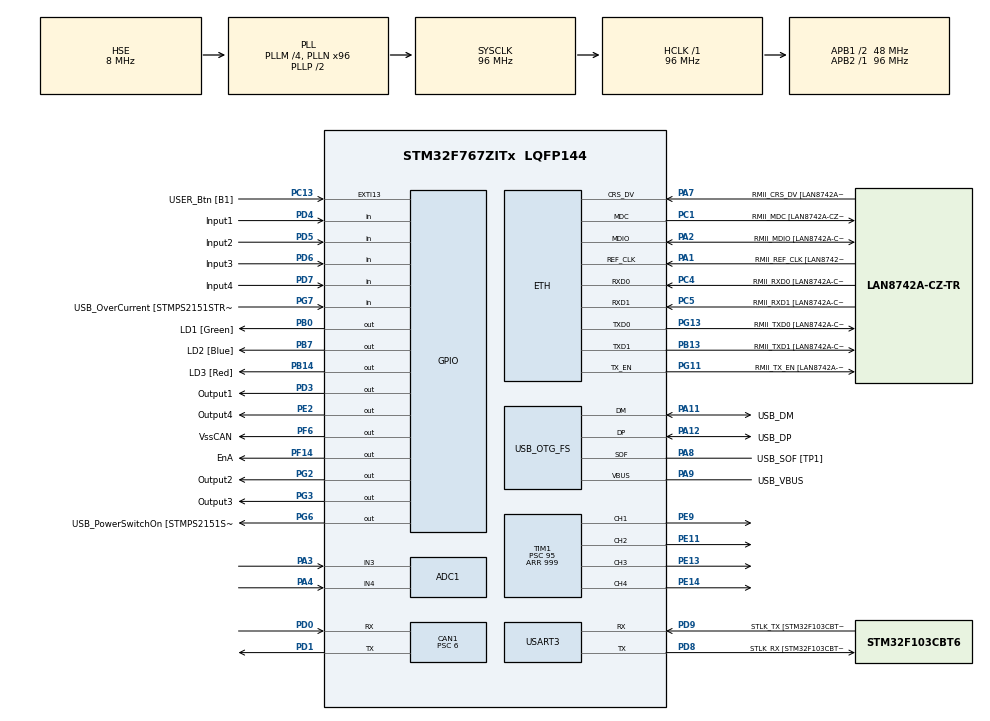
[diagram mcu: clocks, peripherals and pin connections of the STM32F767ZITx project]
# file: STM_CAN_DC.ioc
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ADC1.Channel-0\#ChannelRegularConversion=ADC_CHANNEL_3
ADC1.Channel-1\#ChannelRegularConversion=ADC_CHANNEL_4
ADC1.DMAContinuousRequests=ENABLE
ADC1.ExternalTrigConv=ADC_EXTERNALTRIGCONV_T1_TRGO
ADC1.NbrOfConversion=2
ADC1.NbrOfConversionFlag=1
ADC1.Rank-0\#ChannelRegularConversion=1
ADC1.Rank-1\#ChannelRegularConversion=2
ADC1.SamplingTime-0\#ChannelRegularConversion=ADC_SAMPLETIME_3CYCLES
ADC1.SamplingTime-1\#ChannelRegularConversion=ADC_SAMPLETIME_3CYCLES
ADC1.ScanConvMode=ADC_SCAN_ENABLE
ADC1.master=1
CAN1.BS1=CAN_BS1_4TQ
CAN1.BS2=CAN_BS2_3TQ
CAN1.CalculateTimeQuantum=125.0
CAN1.Prescaler=6
Dma.ADC1.0.Direction=DMA_PERIPH_TO_MEMORY
Dma.ADC1.0.FIFOMode=DMA_FIFOMODE_DISABLE
Dma.ADC1.0.Instance=DMA2_Stream0
Dma.ADC1.0.MemDataAlignment=DMA_MDATAALIGN_HALFWORD
Dma.ADC1.0.MemInc=DMA_MINC_ENABLE
Dma.ADC1.0.Mode=DMA_CIRCULAR
Dma.ADC1.0.PeriphDataAlignment=DMA_PDATAALIGN_HALFWORD
Dma.ADC1.0.PeriphInc=DMA_PINC_DISABLE
Dma.ADC1.0.Priority=DMA_PRIORITY_LOW
Dma.Request0=ADC1
ETH.MediaInterface=ETH_MEDIA_INTERFACE_RMII
ETH.PHY_Name=LAN8742A_PHY_ADDRESS
ETH.PHY_Value=0
ETH.PhyAddress=0
Mcu.Family=STM32F7
Mcu.Name=STM32F767ZITx
Mcu.Package=LQFP144
NVIC.CAN1_RX0_IRQn=true\:0\:0\:false\:false\:true\:true\:true
NVIC.CAN1_RX1_IRQn=true\:0\:0\:false\:false\:true\:true\:true
NVIC.CAN1_TX_IRQn=true\:0\:0\:false\:false\:true\:true\:true
NVIC.DMA2_Stream0_IRQn=true\:0\:0\:false\:false\:true\:false\:true
NVIC.EXTI15_10_IRQn=true\:0\:0\:false\:false\:true\:true\:true
NVIC.PriorityGroup=NVIC_PRIORITYGROUP_4
PA1.GPIO_Label=RMII_REF_CLK [LAN8742A-CZ-TR_REFCLK0]
PA1.Mode=RMII
PA1.Signal=ETH_REF_CLK
PA10.GPIO_Label=USB_ID
PA10.Signal=USB_OTG_FS_ID
PA11.GPIO_Label=USB_DM
PA11.Mode=Device_Only
PA11.Signal=USB_OTG_FS_DM
PA12.GPIO_Label=USB_DP
PA12.Mode=Device_Only
PA12.Signal=USB_OTG_FS_DP
PA13.GPIO_Label=TMS
PA13.Mode=Serial_Wire
PA13.Signal=SYS_JTMS-SWDIO
PA14.GPIO_Label=TCK
PA14.Mode=Serial_Wire
PA14.Signal=SYS_JTCK-SWCLK
PA2.GPIO_Label=RMII_MDIO [LAN8742A-CZ-TR_MDIO]
PA2.Mode=RMII
PA2.Signal=ETH_MDIO
PA3.Signal=ADCx_IN3
PA4.Signal=ADCx_IN4
PA7.GPIO_Label=RMII_CRS_DV [LAN8742A-CZ-TR_CRS_DV]
PA7.Mode=RMII
PA7.Signal=ETH_CRS_DV
PA8.GPIO_Label=USB_SOF [TP1]
PA8.Mode=Activate_SOF_FS
PA8.Signal=USB_OTG_FS_SOF
PA9.GPIO_Label=USB_VBUS
PA9.Mode=Activate_VBUS
PA9.Signal=USB_OTG_FS_VBUS
PB0.GPIO_Label=LD1 [Green]
PB0.Signal=GPIO_Output
PB13.GPIO_Label=RMII_TXD1 [LAN8742A-CZ-TR_TXD1]
PB13.Mode=RMII
PB13.Signal=ETH_TXD1
PB14.GPIO_Label=LD3 [Red]
PB14.Signal=GPIO_Output
PB3.GPIO_Label=SWO
PB3.Signal=SYS_JTDO-SWO
PB7.GPIO_Label=LD2 [Blue]
PB7.Signal=GPIO_Output
PC1.GPIO_Label=RMII_MDC [LAN8742A-CZ-TR_MDC]
PC1.Mode=RMII
PC1.Signal=ETH_MDC
PC13.GPIO_Label=USER_Btn [B1]
PC13.Signal=GPXTI13
PC14/OSC32_IN.Mode=LSE-External-Oscillator
PC14/OSC32_IN.Signal=RCC_OSC32_IN
PC15/OSC32_OUT.Mode=LSE-External-Oscillator
PC15/OSC32_OUT.Signal=RCC_OSC32_OUT
PC4.GPIO_Label=RMII_RXD0 [LAN8742A-CZ-TR_RXD0]
PC4.Mode=RMII
PC4.Signal=ETH_RXD0
PC5.GPIO_Label=RMII_RXD1 [LAN8742A-CZ-TR_RXD1]
PC5.Mode=RMII
PC5.Signal=ETH_RXD1
PD0.GPIO_PuPd=GPIO_PULLUP
PD0.Mode=Master
PD0.Signal=CAN1_RX
PD1.Mode=Master
PD1.Signal=CAN1_TX
PD3.GPIO_Label=Output1
PD3.Signal=GPIO_Output
PD4.GPIO_Label=Input1
PD4.Signal=GPIO_Input
PD5.GPIO_Label=Input2
PD5.Signal=GPIO_Input
PD6.GPIO_Label=Input3
PD6.Signal=GPIO_Input
PD7.GPIO_Label=Input4
PD7.Signal=GPIO_Input
PD8.GPIO_Label=STLK_RX [STM32F103CBT6_PA3]
PD8.Mode=Asynchronous
PD8.Signal=USART3_TX
PD9.GPIO_Label=STLK_TX [STM32F103CBT6_PA2]
PD9.Mode=Asynchronous
PD9.Signal=USART3_RX
PE11.Signal=S_TIM1_CH2
PE13.Signal=S_TIM1_CH3
PE14.Signal=S_TIM1_CH4
PE2.GPIO_Label=Output4
PE2.Signal=GPIO_Output
PE9.Signal=S_TIM1_CH1
PF14.GPIO_Label=EnA
PF14.PinState=GPIO_PIN_SET
PF14.Signal=GPIO_Output
PF6.GPIO_Label=VssCAN
PF6.GPIO_PuPd=GPIO_PULLUP
PF6.PinState=GPIO_PIN_SET
PF6.Signal=GPIO_Output
PG11.GPIO_Label=RMII_TX_EN [LAN8742A-CZ-TR_TXEN]
PG11.Mode=RMII
PG11.Signal=ETH_TX_EN
PG13.GPIO_Label=RMII_TXD0 [LAN8742A-CZ-TR_TXD0]
PG13.Mode=RMII
PG13.Signal=ETH_TXD0
PG2.GPIO_Label=Output2
PG2.Signal=GPIO_Output
PG3.GPIO_Label=Output3
PG3.Signal=GPIO_Output
PG6.GPIO_Label=USB_PowerSwitchOn [STMPS2151STR_EN]
PG6.Signal=GPIO_Output
PG7.GPIO_Label=USB_OverCurrent [STMPS2151STR_FAULT]
PG7.Signal=GPIO_Input
PH0/OSC_IN.GPIO_Label=MCO [STM32F103CBT6_PA8]
PH0/OSC_IN.Mode=HSE-External-Clock-Source
PH0/OSC_IN.Signal=RCC_OSC_IN
PH1/OSC_OUT.Mode=HSE-External-Clock-Source
PH1/OSC_OUT.Signal=RCC_OSC_OUT
ProjectManager.HeapSize=0x400
ProjectManager.StackSize=0x800
ProjectManager.TargetToolchain=Makefile
RCC.48MHZClocksFreq_Value=24000000
RCC.AHBFreq_Value=96000000
RCC.APB1CLKDivider=RCC_HCLK_DIV2
RCC.APB1Freq_Value=48000000
RCC.APB1TimFreq_Value=96000000
RCC.APB2Freq_Value=96000000
RCC.APB2TimFreq_Value=96000000
RCC.CortexFreq_Value=96000000
RCC.HCLKFreq_Value=96000000
RCC.HSE_VALUE=8000000
RCC.HSI_VALUE=16000000
RCC.PLLM=4
RCC.PLLMUL=RCC_PLL_MUL9
RCC.PLLN=96
RCC.PLLQ=4
RCC.PRESCALERUSB=RCC_USBCLKSOURCE_PLL_DIV1_5
RCC.SYSCLKFreq_VALUE=96000000
RCC.SYSCLKSource=RCC_SYSCLKSOURCE_PLLCLK
RCC.SYSCLKSourceVirtual=RCC_SYSCLKSOURCE_PLLCLK
RCC.USBFreq_Value=48000000
RCC.VCOOutputFreq_Value=192000000
SH.ADCx_IN3.0=ADC1_IN3,IN3
SH.ADCx_IN4.0=ADC1_IN4,IN4
SH.S_TIM1_CH1.0=TIM1_CH1,PWM Generation1 CH1
SH.S_TIM1_CH2.0=TIM1_CH2,PWM Generation2 CH2
SH.S_TIM1_CH3.0=TIM1_CH3,PWM Generation3 CH3
SH.S_TIM1_CH4.0=TIM1_CH4,PWM Generation4 CH4
TIM1.AutoReloadPreload=TIM_AUTORELOAD_PRELOAD_ENABLE
TIM1.Channel-PWM\ Generation1\ CH1=TIM_CHANNEL_1
TIM1.Channel-PWM\ Generation2\ CH2=TIM_CHANNEL_2
TIM1.Channel-PWM\ Generation3\ CH3=TIM_CHANNEL_3
TIM1.Channel-PWM\ Generation4\ CH4=TIM_CHANNEL_4
TIM1.CounterMode=TIM_COUNTERMODE_CENTERALIGNED2
TIM1.Period=999
TIM1.Prescaler=95
TIM1.TIM_MasterOutputTrigger=TIM_TRGO_UPDATE
USART3.VirtualMode-Asynchronous=VM_ASYNC
USB_OTG_FS.VirtualMode=Device_Only
VP_TIM1_VS_ClockSourceINT.Mode=Internal
board=NUCLEO-F767ZI

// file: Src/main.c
/* USER CODE BEGIN Header */
/**
  ******************************************************************************
  * @file           : main.c
  * @brief          : Main program body
  ******************************************************************************
  * @attention
  *
  * <h2><center>&copy; Copyright (c) 2021 STMicroelectronics.
  * All rights reserved.</center></h2>
  *
  * This software component is licensed by ST under BSD 3-Clause license,
  * the "License"; You may not use this file except in compliance with the
  * License. You may obtain a copy of the License at:
  *                        opensource.org/licenses/BSD-3-Clause
  *
  ******************************************************************************
  */
/* USER CODE END Header */

#include "main.h"
#include "adc.h"
#include "can.h"
#include "dma.h"
#include "eth.h"
#include "tim.h"
#include "usart.h"
#include "usb_otg.h"
#include "gpio.h"

void SystemClock_Config(void);

int main(void)
{

  /* MCU Configuration--------------------------------------------------------*/

  /* Reset of all peripherals, Initializes the Flash interface and the Systick. */
  HAL_Init();

  /* Configure the system clock */
  SystemClock_Config();

  /* Initialize all configured peripherals */
  MX_GPIO_Init();
  MX_DMA_Init();
  MX_CAN1_Init();
  MX_ETH_Init();
  MX_USART3_UART_Init();
  MX_USB_OTG_FS_PCD_Init();
  MX_TIM1_Init();
  MX_ADC1_Init();
  /* USER CODE BEGIN 2 */

  canopen_link_init();
  dc_motor_init();
  module_init();

  /* USER CODE END 2 */

  /* Infinite loop */
  while (1)
  {

    /* USER CODE BEGIN 3 */
    canopen_link_poll();
    dc_motor_poll();
    module_poll();
  }
  /* USER CODE END 3 */
}

void SystemClock_Config(void)
{
  RCC_OscInitTypeDef RCC_OscInitStruct = {0};
  RCC_ClkInitTypeDef RCC_ClkInitStruct = {0};
  RCC_PeriphCLKInitTypeDef PeriphClkInitStruct = {0};

  /** Configure LSE Drive Capability
  */
  HAL_PWR_EnableBkUpAccess();
  /** Configure the main internal regulator output voltage
  */
  __HAL_RCC_PWR_CLK_ENABLE();
  __HAL_PWR_VOLTAGESCALING_CONFIG(PWR_REGULATOR_VOLTAGE_SCALE3);
  /** Initializes the CPU, AHB and APB busses clocks
  */
  RCC_OscInitStruct.OscillatorType = RCC_OSCILLATORTYPE_HSE;
  RCC_OscInitStruct.HSEState = RCC_HSE_BYPASS;
  RCC_OscInitStruct.PLL.PLLState = RCC_PLL_ON;
  RCC_OscInitStruct.PLL.PLLSource = RCC_PLLSOURCE_HSE;
  RCC_OscInitStruct.PLL.PLLM = 4;
  RCC_OscInitStruct.PLL.PLLN = 96;
  RCC_OscInitStruct.PLL.PLLP = RCC_PLLP_DIV2;
  RCC_OscInitStruct.PLL.PLLQ = 4;
  if (HAL_RCC_OscConfig(&RCC_OscInitStruct) != HAL_OK)
  {
    Error_Handler();
  }
  /** Activate the Over-Drive mode
  */
  if (HAL_PWREx_EnableOverDrive() != HAL_OK)
  {
    Error_Handler();
  }
  /** Initializes the CPU, AHB and APB busses clocks
  */
  RCC_ClkInitStruct.ClockType = RCC_CLOCKTYPE_HCLK|RCC_CLOCKTYPE_SYSCLK
                              |RCC_CLOCKTYPE_PCLK1|RCC_CLOCKTYPE_PCLK2;
  RCC_ClkInitStruct.SYSCLKSource = RCC_SYSCLKSOURCE_PLLCLK;
  RCC_ClkInitStruct.AHBCLKDivider = RCC_SYSCLK_DIV1;
  RCC_ClkInitStruct.APB1CLKDivider = RCC_HCLK_DIV2;
  RCC_ClkInitStruct.APB2CLKDivider = RCC_HCLK_DIV1;

  if (HAL_RCC_ClockConfig(&RCC_ClkInitStruct, FLASH_LATENCY_3) != HAL_OK)
  {
    Error_Handler();
  }
  PeriphClkInitStruct.PeriphClockSelection = RCC_PERIPHCLK_USART3|RCC_PERIPHCLK_CLK48;
  PeriphClkInitStruct.Usart3ClockSelection = RCC_USART3CLKSOURCE_PCLK1;
  PeriphClkInitStruct.Clk48ClockSelection = RCC_CLK48SOURCE_PLL;
  if (HAL_RCCEx_PeriphCLKConfig(&PeriphClkInitStruct) != HAL_OK)
  {
    Error_Handler();
  }
}

void Error_Handler(void)
{
}

/************************ (C) COPYRIGHT STMicroelectronics *****END OF FILE****/
